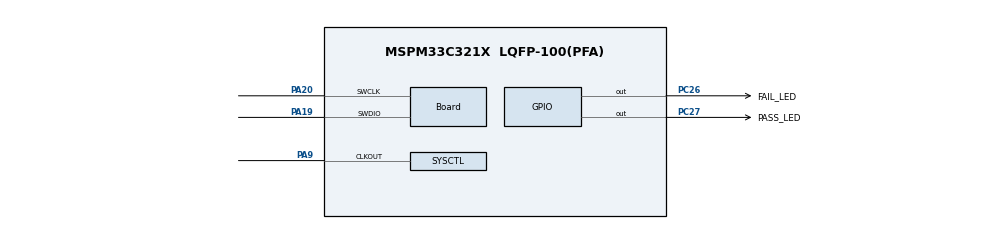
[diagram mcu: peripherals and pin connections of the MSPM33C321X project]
/**
 * @cliArgs --device "MSPM33C321X" --part "Default" --package "LQFP-100(PFA)" --product "mspm33_sdk@1.02.00.00"
 * @versions {"tool":"1.26.0+4407"}
 */
// @cliArgs --board /ti/boards/LP_MSPM33C321A --rtos nortos

/**
 * Import the modules used in this configuration.
 */
const DMA           = scripting.addModule("/ti/driverlib/DMA", {}, false);
const DMA1          = DMA.addInstance();
const GPIO          = scripting.addModule("/ti/driverlib/GPIO", {}, false);
const GPIO1         = GPIO.addInstance();
const MCUBOOT       = scripting.addModule("/ti/driverlib/MCUBOOT");
const NONMAIN       = scripting.addModule("/ti/driverlib/NONMAIN");
const PKA           = scripting.addModule("/ti/driverlib/PKA");
const SHAW          = scripting.addModule("/ti/driverlib/SHAW");
const SYSCTL        = scripting.addModule("/ti/driverlib/SYSCTL");
const ProjectConfig = scripting.addModule("/ti/project_config/ProjectConfig");

/**
 * Write custom configuration values to the imported modules.
 */
DMA1.$name = "DMA0";

const Board                       = scripting.addModule("/ti/driverlib/Board", {}, false);
Board.peripheral.$assign          = "DEBUGSS";
Board.peripheral.swclkPin.$assign = "PA20";
Board.peripheral.swdioPin.$assign = "PA19";

GPIO1.$name                               = "GPIO_LEDS";
GPIO1.associatedPins.create(2);
GPIO1.associatedPins[0].launchPadShortcut = "LED2GreenEn";
GPIO1.associatedPins[0].$name             = "PASS_LED";
GPIO1.associatedPins[0].pin.$assign       = "PC27";
GPIO1.associatedPins[1].launchPadShortcut = "LED2RedEn";
GPIO1.associatedPins[1].$name             = "FAIL_LED";
GPIO1.associatedPins[1].pin.$assign       = "PC26";

MCUBOOT.enableHWSHA256       = true;
MCUBOOT.enablebothECDSAMLDSA = true;
MCUBOOT.enableMLDSA          = true;
MCUBOOT.primaryBase1         = 0x00010000;
MCUBOOT.primarySize1         = 0x000030C0;
MCUBOOT.secondarySize1       = 0x000030C0;
MCUBOOT.enableECDSA          = true;
MCUBOOT.secondaryBase1       = 0x00090000;

NONMAIN.nonmainWarning = true;
NONMAIN.cscExists      = true;
NONMAIN.flashBankSwap  = true;

SHAW.algorithm                             = "DL_SHAW_ALGORITHM_SHA_256";
SHAW.enabledDMAEvent1Triggers              = "DL_SHAW_TRIGGER";
SHAW.DMA_CHANNEL_EVENT1.$name              = "CH0";
SHAW.DMA_CHANNEL_EVENT1.transferMode       = "SINGLE_BLOCK";
SHAW.DMA_CHANNEL_EVENT1.srcIncrement       = "INCREMENT";
SHAW.DMA_CHANNEL_EVENT1.enableInterrupt    = true;
SHAW.DMA_CHANNEL_EVENT1.peripheral.$assign = "DMA0_CH0";

SYSCTL.forceDefaultClkConfig        = true;
SYSCTL.MCLKSource                   = "HSCLK";
SYSCTL.enableEXCLK                  = true;
SYSCTL.EXCLKSource                  = "ULPCLK";
SYSCTL.EXCLKDivider                 = "16";
SYSCTL.SYSPLL_Pdiv                  = 1;
SYSCTL.SYSPLL_CLK0En                = true;
SYSCTL.SYSPLL_CLK1En                = true;
SYSCTL.SYSPLL_CLK2XEn               = true;
SYSCTL.peripheral.$assign           = "SYSCTL";
SYSCTL.peripheral.clkOutPin.$assign = "PA9";

ProjectConfig.migrationCondition = true;
ProjectConfig.genLinker = false;
ProjectConfig.genStartup = false;
ProjectConfig.genOpts = false;
ProjectConfig.genLibs = false;
